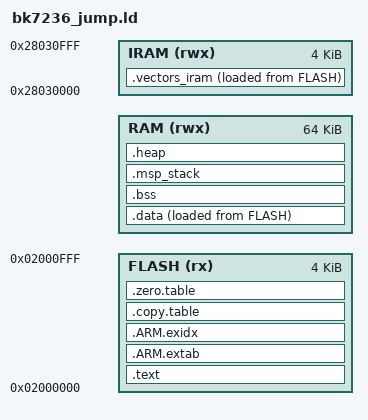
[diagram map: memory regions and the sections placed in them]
;/*
; * Copyright (c) 2017-2020 Arm Limited
; *
; * Licensed under the Apache License, Version 2.0 (the "License");
; * you may not use this file except in compliance with the License.
; * You may obtain a copy of the License at
; *
; *     http://www.apache.org/licenses/LICENSE-2.0
; *
; * Unless required by applicable law or agreed to in writing, software
; * distributed under the License is distributed on an "AS IS" BASIS,
; * WITHOUT WARRANTIES OR CONDITIONS OF ANY KIND, either express or implied.
; * See the License for the specific language governing permissions and
; * limitations under the License.
; *
; *
; * This file is derivative of CMSIS V5.00 gcc_arm.ld
; */

/* Linker script to configure memory regions. */
/* This file will be run trough the pre-processor. */

#include "region_defs.h"

MEMORY
{
  FLASH (rx)  : ORIGIN = 0x02000000, LENGTH = 0x1000
  RAM   (rwx) : ORIGIN = BL2_DATA_START, LENGTH = 0x10000
  IRAM (rwx)  : ORIGIN = 0x28030000, LENGTH = 0x1000

}

__heap_size__  = 0x4000;
__msp_stack_size__ = 0x4800;

/* Library configurations */
GROUP(libgcc.a libc.a libm.a libnosys.a)

ENTRY(Reset_Handler)

SECTIONS
{
    .text :
    {
        KEEP(*(.vectors))
        __Vectors_End = .;
        __Vectors_Size = __Vectors_End - __Vectors;
        __end__ = .;
        *(.fix.reset_entry)
        EXCLUDE_FILE
            (
            system.o bl_extflash.o bl_spi.o
            )
        *(.text*)
        KEEP(*(.init))
        KEEP(*(.fini))
        *(.rodata*)
    } > FLASH

    .ARM.extab :
    {
        *(.ARM.extab* .gnu.linkonce.armextab.*)
    } > FLASH

    __exidx_start = .;
    .ARM.exidx :
    {
        *(.ARM.exidx* .gnu.linkonce.armexidx.*)
    } > FLASH
    __exidx_end = .;

    /* To copy multiple ROM to RAM sections,
     * define etext2/data2_start/data2_end and
     * define __STARTUP_COPY_MULTIPLE in startup_cmsdk_bk7236_bl2.S */
    .copy.table :
    {
        . = ALIGN(4);
        __copy_table_start__ = .;
        LONG (LOADADDR(.data))
        LONG (ADDR(.data))
        LONG (SIZEOF(.data))

        LONG (LOADADDR(.vectors_iram))
        LONG (ADDR(.vectors_iram))
        LONG (SIZEOF(.vectors_iram))
        __copy_table_end__ = .;
    } > FLASH

    /* To clear multiple BSS sections,
     * uncomment .zero.table section and,
     * define __STARTUP_CLEAR_BSS_MULTIPLE in startup_cmsdk_bk7236_bl2.S */
    .zero.table :
    {
        . = ALIGN(4);
        __zero_table_start__ = .;
        LONG (ADDR(.bss))
        LONG (SIZEOF(.bss))
        __zero_table_end__ = .;
    } > FLASH

    .vectors_iram :
    {
        . = ALIGN(512);
        __vector_iram_table = .;
        KEEP(*(.vectors_iram))
        . = ALIGN(4);
        *system.o(.text.* *.rodata *.rodata.*)
        *bl_extflash.o(.text.* *.rodata *.rodata.*)
        *bl_spi.o(.text.* *.rodata *.rodata.*)
    } > IRAM AT > FLASH

    .data : ALIGN(4)
    {
        *(.data*)
    } > RAM AT > FLASH
    Image$$ER_DATA$$Base = ADDR(.data);

    .bss : ALIGN(4)
    {
        __bss_start__ = .;
        *(.bss*)
        *(COMMON)
        . = ALIGN(4);
        __bss_end__ = .;
    } > RAM AT > RAM

    .msp_stack : ALIGN(32)
    {
        . += __msp_stack_size__;
    } > RAM
    Image$$ARM_LIB_STACK$$ZI$$Base = ADDR(.msp_stack);
    Image$$ARM_LIB_STACK$$ZI$$Limit = ADDR(.msp_stack) + SIZEOF(.msp_stack);

    .heap : ALIGN(8)
    {
        __end__ = .;
        PROVIDE(end = .);
        __HeapBase = .;
        . += __heap_size__;
        __HeapLimit = .;
        __heap_limit = .; /* Add for _sbrk */
    } > RAM
    Image$$ARM_LIB_HEAP$$ZI$$Base = ADDR(.heap);
    Image$$ARM_LIB_HEAP$$ZI$$Limit = ADDR(.heap) + SIZEOF(.heap);

    PROVIDE(__stack = Image$$ARM_LIB_STACK$$ZI$$Limit);
}
